# ATUC256L3U device description
Architecture: AVR32_UC3; Family: AVR UC3
Registers are 32-bit, read-write, reset 0x0 unless marked. A register's access mark holds for its fields unless they carry their own. Offsets are from the block's base; [hi:lo] are bit positions; lines under a group give offsets from that group; {n}, {i} and the like mark numbered series; 'fields as' and 'values as' point back to an identical list.

## FLASHCDW — Flash Controller
Instances: FLASHCDW 0xfffe0000
Parameters: GPF_NUM=32
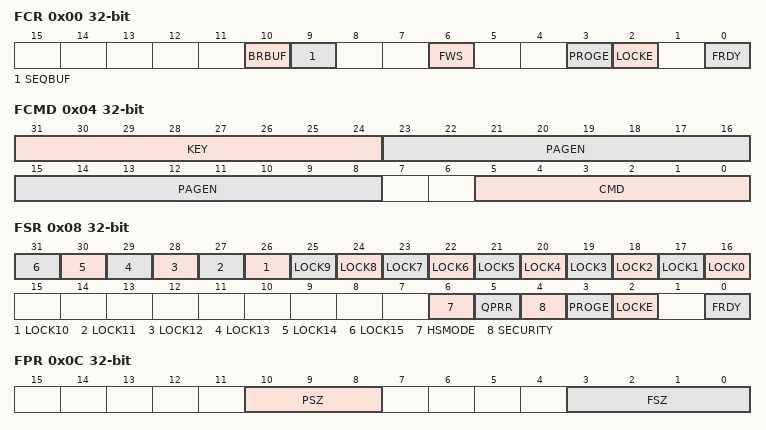
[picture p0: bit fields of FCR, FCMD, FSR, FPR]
0x00 FCR — Flash Controller Control Register
  [10] BRBUF — Branch Target Instruction Buffer Enable
  [9] SEQBUF — Sequential Instruction Fetch Buffer Enable
  [6] FWS — Flash Wait State
  [3] PROGE — Programming Error Interrupt Enable
  [2] LOCKE — Lock Error Interrupt Enable
  [0] FRDY — Flash Ready Interrupt Enable
0x04 FCMD — Flash Controller Command Register
  [31:24] KEY — Write protection key
    165=KEY
  [23:8] PAGEN — Page number
  [5:0] CMD — Command
    0=NOP; 1=WP; 2=EP; 3=CPB; 4=LP; 5=UP; 6=EA; 7=WGPB; 8=EGPB; 9=SSB; 10=PGPFB; 11=EAGPF; 12=QPR; 13=WUP; 14=EUP; 15=QPRUP; 16=HSEN; 17=HSDIS
0x08 FSR reset not defined — Flash Controller Status Register
  [n+16] LOCK{n} (n=0..15) — Lock Region {n} Lock Status
  [6] HSMODE — High Speed Mode
  [5] QPRR — Quick Page Read Result
  [4] SECURITY — Security Bit Status
  [3] PROGE — Programming Error Status
  [2] LOCKE — Lock Error Status
  [0] FRDY — Flash Ready Status
0x0C FPR ro reset not defined — Flash Controller Parameter Register
  [10:8] PSZ — Page Size
  [3:0] FSZ — Flash Size
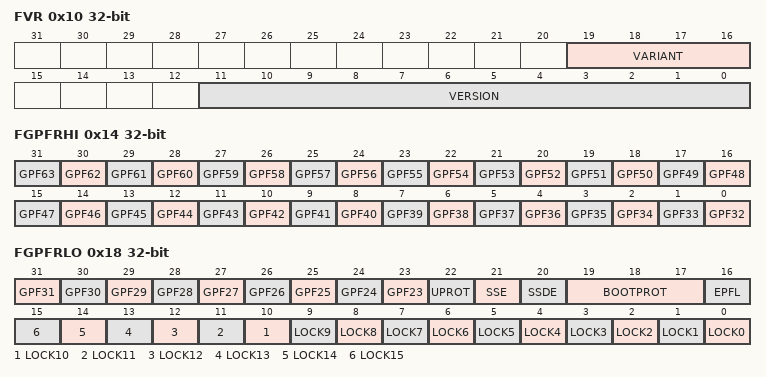
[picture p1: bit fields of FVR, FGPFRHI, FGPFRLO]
0x10 FVR ro reset not defined — Flash Controller Version Register
  [19:16] VARIANT — Variant Number
  [11:0] VERSION — Version Number
0x14 FGPFRHI ro reset not defined — Flash Controller General Purpose Fuse Register High
  [n-32] GPF{n} (n=32..63) — General Purpose Fuse {n}
0x18 FGPFRLO ro reset not defined — Flash Controller General Purpose Fuse Register Low
  [n] GPF{n} (n=23..31) — General Purpose Fuse {n}
  [22] UPROT — Jtag user protection
  [21] SSE — Secure state enable
  [20] SSDE — Secure state debug enable
  [19:17] BOOTPROT — Boot Section Protection size
  [16] EPFL — External Privileged mode fetch lock
  [n] LOCK{n} (n=0..15) — Lock Bit {n}

## FREQM — Frequency Meter
Instances: FREQM 0xffff2800
0x00 CTRL wo — Control register
  [0] START — Start frequency measurement
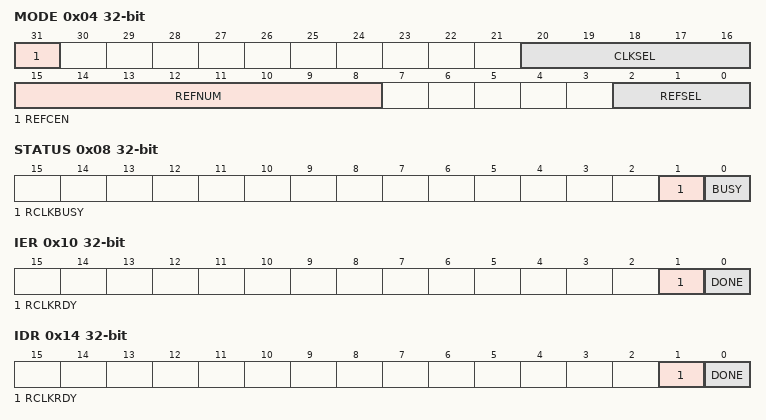
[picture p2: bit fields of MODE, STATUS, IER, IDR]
0x04 MODE
  [31] REFCEN — Reference Clock Enable
  [20:16] CLKSEL — Clock Source Selection
  [15:8] REFNUM — Number of Reference CLock Cycles
  [2:0] REFSEL — Reference Clock Selection
0x08 STATUS ro
  [1] RCLKBUSY — Reference Clock Busy
  [0] BUSY — Frequency measurement on-going
0x0C VALUE ro
  [23:0] VALUE — Measured frequency
0x10 IER wo — Interrupt Enable Register
  [1] RCLKRDY — Reference Clock ready
  [0] DONE — Frequency measurment done
0x14 IDR wo — Interrupt Diable Register
  fields as IER
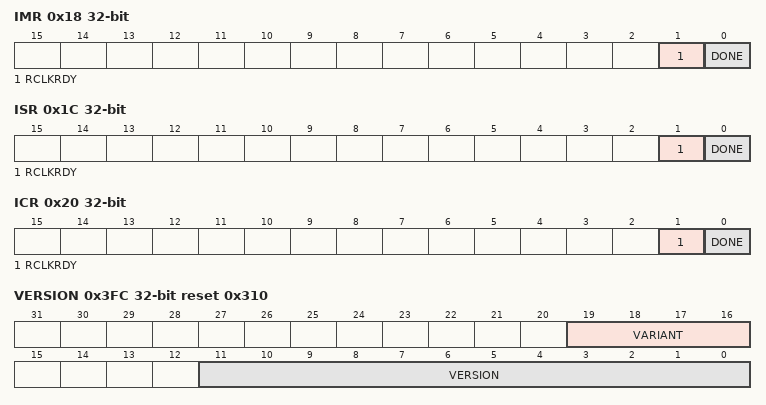
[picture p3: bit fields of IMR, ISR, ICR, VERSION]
0x18 IMR ro — Interrupt Mask Register
  fields as IER
0x1C ISR ro — Interrupt Status Register
  fields as IER
0x20 ICR wo — Interrupt Clear Register
  fields as IER
0x3FC VERSION ro reset 0x310
  [19:16] VARIANT — Variant number
  [11:0] VERSION — Version number

## GLOC — Glue Logic Controller
Instances: GLOC 0xffff6c00
{0x0+8i} LUT[{i}] (i=0..6) group
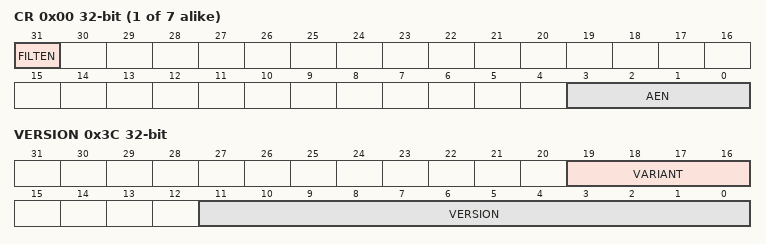
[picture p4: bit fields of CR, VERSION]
  0x00 CR — Control Register
    [31] FILTEN — Filter enable
    [3:0] AEN — Input mask
  0x04 TRUTH
    [15:0] TRUTH
0x38 PARAMETER ro reset not defined
  [7:0] LUTS
0x3C VERSION ro reset not defined
  [19:16] VARIANT, [11:0] VERSION

## HMATRIXB — HSB Matrix
Instances: HMATRIXB 0xfffe0400
{0x0+4i} mcfg[{i}] (i=0..15) access not given reset 0x2
  [2:0] ULBT — Undefined Length Burst Type
    0=INFINITE; 1=SINGLE; 2=FOUR_BEAT; 3=EIGHT_BEAT; 4=SIXTEEN_BEAT
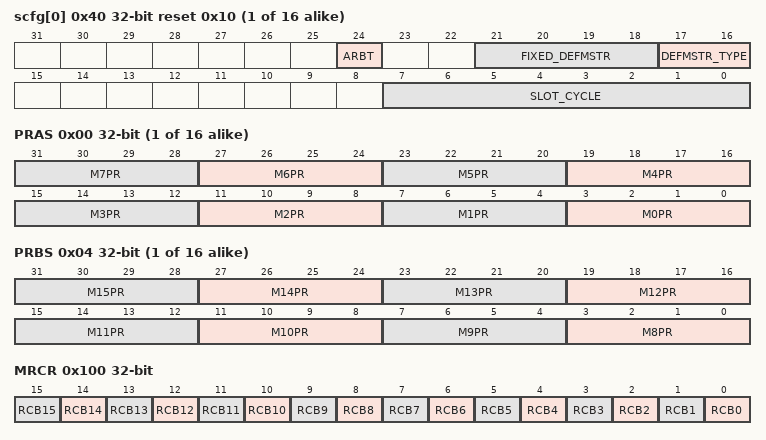
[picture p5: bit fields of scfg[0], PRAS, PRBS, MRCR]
{0x40+4i} scfg[{i}] (i=0..15) access not given reset 0x10
  [24] ARBT — Arbitration Type
    0=ROUND_ROBIN; 1=FIXED_PRIORITY
  [21:18] FIXED_DEFMSTR — Fixed Index of Default Master
  [17:16] DEFMSTR_TYPE — Default Master Type
    0=NO_DEFAULT; 1=LAST_DEFAULT; 2=FIXED_DEFAULT
  [7:0] SLOT_CYCLE — Maximum Number of Allowed Cycles for a Burst
{0x80+8i} prs[{i}] (i=0..15) group
  0x00 PRAS — Priority Register A for Slave 0
    [4n+3:4n] M{n}PR (n=0..7) — Master {n} Priority
  0x04 PRBS — Priority Register B for Slave 0
    [4n-29:4n-32] M{n}PR (n=8..15) — Master {n} Priority
0x100 MRCR — Master Remap Control Register
  [n] RCB{n} (n=0..15) — Remap Command bit for Master {n}
{0x110+4i} sfr[{i}] (i=0..15) access not given
  [31:0] SFR — Special Function Register
